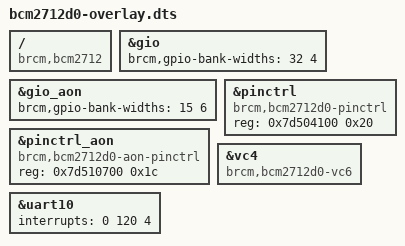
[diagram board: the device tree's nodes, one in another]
// SPDX-License-Identifier: GPL-2.0
// Mainline-compatible replacement for the bcm2712d0.dtbo shipped by
// raspberrypi/firmware. The upstream version includes fragments targeting
// &spi10 and &dma40 which are not present in the mainline BCM2712 symbol
// table. The GPU firmware aborts the entire overlay on the first unresolved
// symbol, so D0 silicon ends up with C0 pinctrl addresses and panics.
//
// This file omits those fragments (6-8). Remove this file and the dtc build
// step from the PKGBUILD once the upstream raspberrypi/firmware fix is merged.
/dts-v1/;
/plugin/;

/ {
	compatible = "brcm,bcm2712";

	fragment@0 {
		target = <&gio>;
		__overlay__ {
			brcm,gpio-bank-widths = <32 4>;
		};
	};

	fragment@1 {
		target = <&gio_aon>;
		__overlay__ {
			brcm,gpio-bank-widths = <15 6>;
		};
	};

	// D0 pinctrl base: 0x7d504100 (C0 uses the same base but size 0x30;
	// D0 driver only accesses 0x00-0x1f so restrict the mapping).
	fragment@2 {
		target = <&pinctrl>;
		__overlay__ {
			compatible = "brcm,bcm2712d0-pinctrl";
			reg = <0x7d504100 0x20>;
		};
	};

	fragment@3 {
		target = <&pinctrl_aon>;
		__overlay__ {
			compatible = "brcm,bcm2712d0-aon-pinctrl";
			reg = <0x7d510700 0x1c>;
		};
	};

	fragment@4 {
		target = <&vc4>;
		__overlay__ {
			compatible = "brcm,bcm2712d0-vc6";
		};
	};

	fragment@5 {
		target = <&uart10>;
		__overlay__ {
			interrupts = <0 120 4>;
		};
	};
};
